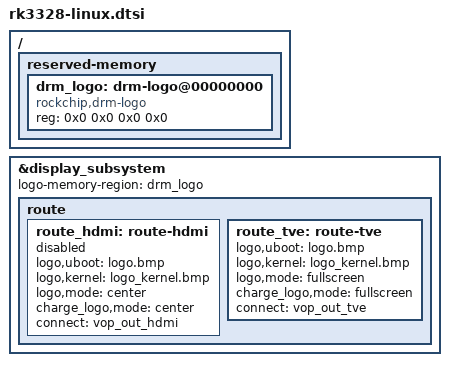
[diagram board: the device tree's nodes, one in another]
/ {

	reserved-memory {
		#address-cells = <2>;
		#size-cells = <2>;
		ranges;

		drm_logo: drm-logo@00000000 {
			compatible = "rockchip,drm-logo";
			reg = <0x0 0x0 0x0 0x0>;
		};
	};
};

&display_subsystem {
	logo-memory-region = <&drm_logo>;
	status = "okay";
	route {
		route_hdmi: route-hdmi {
			status = "disabled";
			logo,uboot = "logo.bmp";
			logo,kernel = "logo_kernel.bmp";
			logo,mode = "center";
			charge_logo,mode = "center";
			connect = <&vop_out_hdmi>;
		};

		route_tve: route-tve {
			status = "okay";
			logo,uboot = "logo.bmp";
			logo,kernel = "logo_kernel.bmp";
			logo,mode = "fullscreen";
			charge_logo,mode = "fullscreen";
			connect = <&vop_out_tve>;
		};
	};
};

